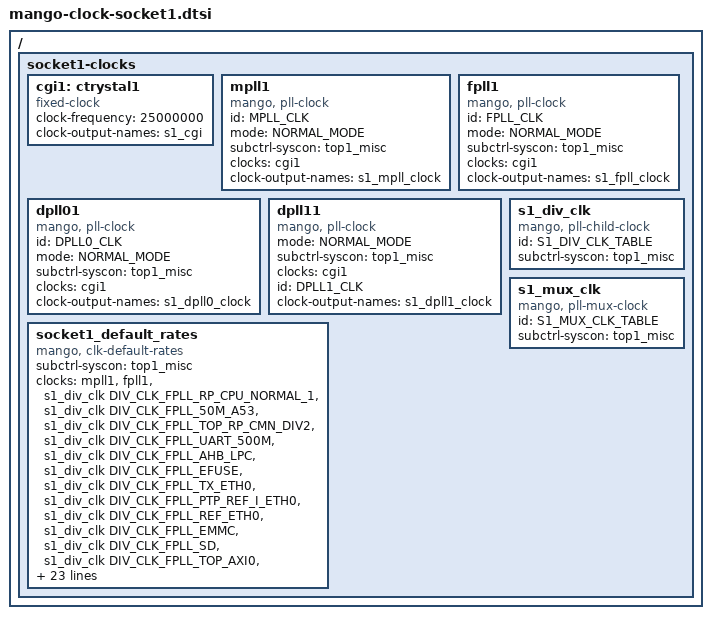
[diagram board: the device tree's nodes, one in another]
/ {
	socket1-clocks {
		#address-cells = <2>;
		#size-cells = <2>;
		ranges;

		cgi1: ctrystal1 {
			compatible = "fixed-clock";
			clock-frequency = <25000000>;
			clock-output-names = "s1_cgi";
			#clock-cells = <0>;
		};

		/* pll clock */
		mpll1: mpll1 {
			compatible = "mango, pll-clock";
			#clock-cells = <0>;
			id = <MPLL_CLK>;
			mode = <NORMAL_MODE>;
			subctrl-syscon = <&top1_misc>;
			clocks = <&cgi1>;
			clock-output-names = "s1_mpll_clock";
		};

		fpll1: fpll1 {
			compatible = "mango, pll-clock";
			#clock-cells = <0>;
			id = <FPLL_CLK>;
			mode = <NORMAL_MODE>;
			subctrl-syscon = <&top1_misc>;
			clocks = <&cgi1>;
			clock-output-names = "s1_fpll_clock";
		};

		dpll01: dpll01 {
			compatible = "mango, pll-clock";
			#clock-cells = <0>;
			id = <DPLL0_CLK>;
			mode = <NORMAL_MODE>;
			subctrl-syscon = <&top1_misc>;
			clocks = <&cgi1>;
			clock-output-names = "s1_dpll0_clock";
		};

		dpll11: dpll11 {
			compatible = "mango, pll-clock";
			#clock-cells = <0>;
			mode = <NORMAL_MODE>;
			subctrl-syscon = <&top1_misc>;
			clocks = <&cgi1>;
			id = <DPLL1_CLK>;
			clock-output-names = "s1_dpll1_clock";
		};

		s1_div_clk: s1_div_clk {
			compatible = "mango, pll-child-clock";
			#clock-cells = <1>;
			id = <S1_DIV_CLK_TABLE>;
			subctrl-syscon = <&top1_misc>;
		};

		s1_mux_clk: s1_mux_clk {
			compatible = "mango, pll-mux-clock";
			#clock-cells = <1>;
			id = <S1_MUX_CLK_TABLE>;
			subctrl-syscon = <&top1_misc>;
		};

		socket1_default_rates {
			compatible = "mango, clk-default-rates";
			#clock-cells = <1>;
			subctrl-syscon = <&top1_misc>;
			clocks = \
				<&mpll1>, <&fpll1>,

				<&s1_div_clk DIV_CLK_FPLL_RP_CPU_NORMAL_1>,
				<&s1_div_clk DIV_CLK_FPLL_50M_A53>,
				<&s1_div_clk DIV_CLK_FPLL_TOP_RP_CMN_DIV2>,
				<&s1_div_clk DIV_CLK_FPLL_UART_500M>,
				<&s1_div_clk DIV_CLK_FPLL_AHB_LPC>,
				<&s1_div_clk DIV_CLK_FPLL_EFUSE>,
				<&s1_div_clk DIV_CLK_FPLL_TX_ETH0>,
				<&s1_div_clk DIV_CLK_FPLL_PTP_REF_I_ETH0>,
				<&s1_div_clk DIV_CLK_FPLL_REF_ETH0>,
				<&s1_div_clk DIV_CLK_FPLL_EMMC>,
				<&s1_div_clk DIV_CLK_FPLL_SD>,
				<&s1_div_clk DIV_CLK_FPLL_TOP_AXI0>,
				<&s1_div_clk DIV_CLK_FPLL_TOP_AXI_HSPERI>,
				<&s1_div_clk DIV_CLK_FPLL_AXI_DDR_1>,
				<&s1_div_clk DIV_CLK_FPLL_DIV_TIMER1>,
				<&s1_div_clk DIV_CLK_FPLL_DIV_TIMER2>,
				<&s1_div_clk DIV_CLK_FPLL_DIV_TIMER3>,
				<&s1_div_clk DIV_CLK_FPLL_DIV_TIMER4>,
				<&s1_div_clk DIV_CLK_FPLL_DIV_TIMER5>,
				<&s1_div_clk DIV_CLK_FPLL_DIV_TIMER6>,
				<&s1_div_clk DIV_CLK_FPLL_DIV_TIMER7>,
				<&s1_div_clk DIV_CLK_FPLL_DIV_TIMER8>,
				<&s1_div_clk DIV_CLK_FPLL_100K_EMMC>,
				<&s1_div_clk DIV_CLK_FPLL_100K_SD>,
				<&s1_div_clk DIV_CLK_FPLL_GPIO_DB>,

				<&s1_div_clk DIV_CLK_MPLL_RP_CPU_NORMAL_0>,
				<&s1_div_clk DIV_CLK_MPLL_AXI_DDR_0>;

			clock-rates = \
				<2000000000>, <1000000000>,

				<2000000000>, <50000000>,
				<1000000000>, <500000000>,
				<200000000>, <25000000>,
				<125000000>, <50000000>,
				<25000000>, <100000000>,
				<100000000>, <100000000>,
				<250000000>, <1000000000>,
				<50000000>, <50000000>,
				<50000000>, <50000000>,
				<50000000>, <50000000>,
				<50000000>, <50000000>,
				<100000>, <100000>, <100000>,

				<2000000001>, <1000000001>;
		};
	};
};
